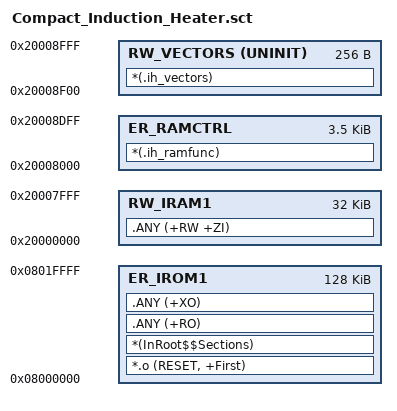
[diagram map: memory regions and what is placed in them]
; IH01A STM32G071CBU6: 128KiB Flash and 36KiB SRAM.
; Preserve Flash RESET vector for boot, copy it to 0x20008F00 at startup,
; and execute only the high-priority ADC DMA ISR from SRAM.
; Memory: RW/ZI 32KiB, RAM ISR up to 3584B, vector reserve 256B,
; with 256B unused guard between code region and vector region.
; All RW/ZI (including 0x400 heap and 0x400 stack) stay in RW_IRAM1.
LR_IROM1 0x08000000 0x00020000 {
  ER_IROM1 0x08000000 0x00020000 {
    *.o (RESET, +First)
    *(InRoot$$Sections)
    .ANY (+RO)
    .ANY (+XO)
  }
  ER_RAMCTRL 0x20008000 0x00000E00 {
    *(.ih_ramfunc)
  }
  RW_IRAM1 0x20000000 0x00008000 {
    .ANY (+RW +ZI)
  }
  RW_VECTORS 0x20008F00 UNINIT 0x00000100 {
    *(.ih_vectors)
  }
}
